# STM32MP21_CA35 register map
File version: 0.4
CPU: CM33 r0p1, little endian, MPU, FPU, vendor SysTick, 8 interrupt priority bits
Registers are 32-bit, read-write, reset 0x0 unless marked. A register's access mark holds for its fields unless they carry their own. Offsets are from the block's base; [hi:lo] are bit positions; {n}, {i} and the like mark numbered series; 'fields as' and 'values as' point back to an identical list.

## FDCAN1 (part 1 of 2) — FDCAN address block description
Base 0x402D0000
Same registers: FDCAN2 0x402E0000, FDCAN1_S 0x502D0000, FDCAN2_S 0x502E0000
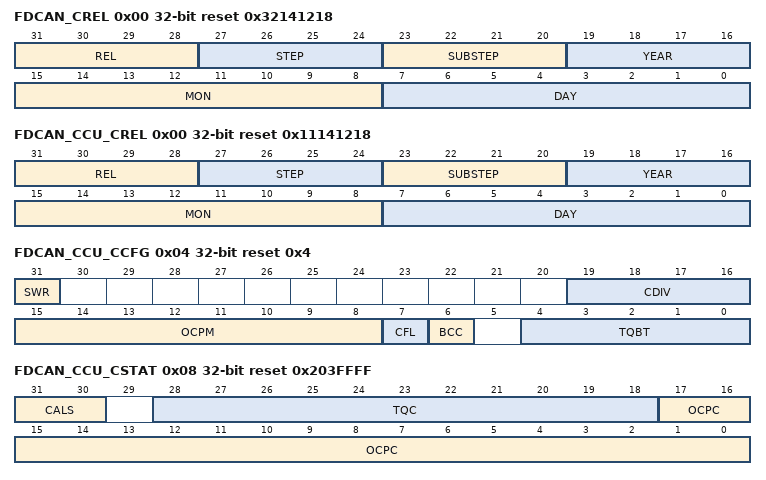
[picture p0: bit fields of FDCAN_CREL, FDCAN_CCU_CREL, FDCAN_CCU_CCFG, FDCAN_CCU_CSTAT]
0x00 FDCAN_CREL ro reset 0x32141218 — FDCAN core release register
  [31:28] REL — Core release = 3
  [27:24] STEP — Step of core release = 2
  [23:20] SUBSTEP — Sub-step of core release = 1
  [19:16] YEAR — Timestamp year = 4
  [15:8] MON — Timestamp month = 12
  [7:0] DAY — Timestamp day =18
0x00 FDCAN_CCU_CREL ro reset 0x11141218 (alternate view of FDCAN_CREL) — Clock calibration unit core release register
  [31:28] REL — Core release = 1
  [27:24] STEP — Step of core release = 1
  [23:20] SUBSTEP — Sub-step of core release = 1
  [19:16] YEAR — Timestamp year =
  [15:8] MON — Timestamp month = 12
  [7:0] DAY — Timestamp day = 18
0x04 FDCAN_ENDN ro reset 0x87654321 — FDCAN Endian register
  [31:0] ETV — Endianness test value The endianness test value is 0x8765 4321.
0x04 FDCAN_CCU_CCFG reset 0x4 (alternate view of FDCAN_ENDN) — Calibration configuration register
  [31] SWR — Software reset Writing a 1 to this bit resets the calibration FSM to state Not_Calibrated (FDCAN_CCU_CSTAT.CALS = 00). The calibration watchdog value CWD.WDV is also reset. Registers FDCAN_CCFG, FDCAN_CCU_CSTAT and the calibration watchdog configuration CWD.WDC are unchanged. The bit remains set until reset is completed. Write access by the user to registers/bits marked with P = Protected Write is possible only when FDCAN control bits FDCAN_CCCR.CCE = 1 AND FDCAN_CCCR.INIT = 1.
  [19:16] CDIV — Clock divider The clock divider must be configured when the clock calibration is bypassed (BCC = 1) to ensure that the FDCAN requirement is fulfilled. Write access by the user to registers/bits marked with P = Protected Write is possible only when FDCAN control bits FDCAN_CCCR.CCE = 1 AND FDCAN_CCCR.INIT = 1.
    0=Divide by 1; 1=Divide by 2; 2=Divide by 4; 3=Divide by 6; 4=Divide by 8; 5=Divide by 10; 6=Divide by 12; 7=Divide by 14; 8=Divide by 16; 9=Divide by 18; 10=Divide by 20; 11=Divide by 22; 12=Divide by 24; 13=Divide by 26; 14=Divide by 28; 15=Divide by 30
  [15:8] OCPM — Oscillator clock periods minimum Configures the minimum number of periods in two CAN bit times. OCPM is used in basic calibration to avoid false measurements in case of glitches on the bus line. The configured number of periods is OCPM 32. The configuration depends on the frequency and the bitrate configured in FDCAN modules (from 125 kbit/s up to 1 Mbit/s). It is recommended to configure a value slightly below two CAN bit times. The reset value is 1.6 bit times at 80 MHz fdcan_ker_ck and 1 Mbit/s CAN bitrate. Write access by the user to registers/bits marked with P = Protected Write is possible only when FDCAN control bits FDCAN_CCCR.CCE = 1 AND FDCAN_CCCR.INIT = 1.
  [7] CFL — Calibration field length Write access by the user to registers/bits marked with P = Protected Write is possible only when FDCAN control bits FDCAN_CCCR.CCE = 1 AND FDCAN_CCCR.INIT = 1.
    0=Calibration field length is 32 bits; 1=Calibration field length is 64 bits
  [6] BCC — Bypass clock calibration If this bit is set, the clock input fdcan_ker_ck is routed to the time quanta clock through a clock divider configurable via CDIV. In this case the baudrate prescaler of the connected FDCANs must be configured to generate the FDCAN internal time quanta clock.
    0=Clock calibration unit generates time quanta clock; 1=Clock calibration unit bypassed (default configuration)
  [4:0] TQBT — Time quanta per bit time Configures the number of time quanta per bit time. Same value as configured in FDCAN modules. The range of the resulting time quanta clock fdcan_tq_ck is from 0.5 MHz (bitrate of 125 kbit/s with 4 tq per bit time) to 25 MHz (bitrate of 1 Mbit/s with 25 tq per bit time). Valid values are 4 to 25. Configured values below 4 are interpreted as 4, values above 25 are interpreted as 25. Write access by the user to registers/bits marked with P = Protected Write is possible only when FDCAN control bits FDCAN_CCCR.CCE = 1 AND FDCAN_CCCR.INIT = 1.
0x08 FDCAN_CCU_CSTAT ro reset 0x203FFFF — Calibration status register
  [31:30] CALS — Calibration state
    0=Not_Calibrated; 1=Basic_Calibrated; 2=Precision_Calibrated
  [28:18] TQC — Time quanta counter Captured number of time quanta in calibration field (32 or 64 bits). Only valid when the clock calibration unit is in state Precision_Calibrated.
  [17:0] OCPC — Oscillator clock period counter Captured number of oscillator clock periods in calibration field (32 or 64 bits). Only valid when the clock calibration unit is in state Precision_Calibrated.
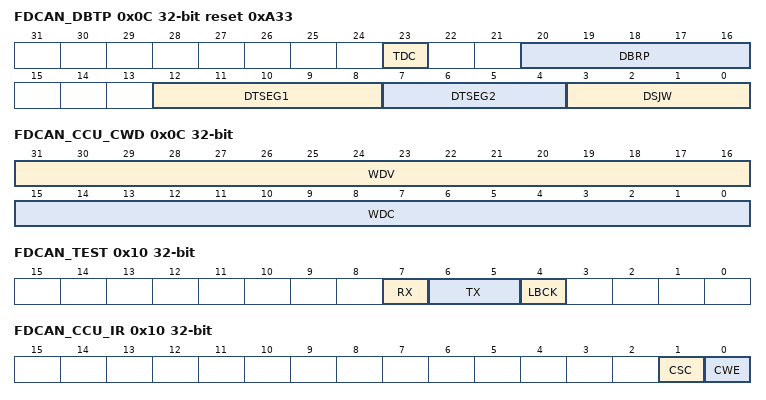
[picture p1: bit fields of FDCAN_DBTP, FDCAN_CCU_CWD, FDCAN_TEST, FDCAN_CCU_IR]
0x0C FDCAN_DBTP reset 0xA33 — FDCAN data bit timing and prescaler register
  [23] TDC — Transceiver delay compensation
    0=Transceiver delay compensation disabled; 1=Transceiver delay compensation enabled
  [20:16] DBRP — Data bitrate prescaler The value by which the oscillator frequency is divided to generate the bit time quanta. The bit time is built up from a multiple of these quanta. Valid values for the baudrate prescaler are 0 to 31. The hardware interpreters this value as the programmed value plus 1.
  [12:8] DTSEG1 — Data time segment before sample point Valid values are 0 to 31. The value used by the hardware is the one programmed, incremented by 1, i.e. tsubsuperiorBS1/subsuperior = (DTSEG1 + 1) x tq.
  [7:4] DTSEG2 — Data time segment after sample point Valid values are 0 to 15. The value used by the hardware is the one programmed, incremented by 1, i.e. tsubsuperiorBS2/subsuperior = (DTSEG2 + 1) x tq.
  [3:0] DSJW — Synchronization jump width Valid values are 0 to 15. The value used by the hardware is the one programmed, incremented by 1, i.e. tsubsuperiorSJW/subsuperior = (DSJW + 1) x tq.
0x0C FDCAN_CCU_CWD (alternate view of FDCAN_DBTP) — Calibration watchdog register
  [31:16] WDV ro — Watchdog value Actual calibration watchdog counter value.
  [15:0] WDC — WDC Watchdog configuration Start value of the calibration watchdog counter. With the reset value of 00 the counter is disabled. Write access by the user to registers/bits marked with P = Protected Write is possible only when FDCAN control bits FDCAN_CCCR.CCE = 1 AND FDCAN_CCCR.INIT = 1.
0x10 FDCAN_TEST
  [7] RX ro — Receive pin Monitors the actual value of transmit pin FDCANx_RX
    0=The CAN bus is dominant (FDCANx_RX = 0); 1=The CAN bus is recessive (FDCANx_RX = 1)
  [6:5] TX — Control of transmit pin
    0=Reset value , FDCANx_TX TX is controlled by the CAN core, updated at the end of the CAN bit time; 1=Sample point can be monitored at pin FDCANx_TX; 2=Dominant (0) level at pin FDCANx_TX; 3=Recessive (1) at pin FDCANx_TX
  [4] LBCK — Loop back mode
    0=Reset value, loop back mode is disabled; 1=Loop back mode is enabled (see Test modes)
0x10 FDCAN_CCU_IR (alternate view of FDCAN_TEST) — Clock calibration unit interrupt register
  [1] CSC — Calibration state changed
    0=Calibration state unchanged; 1=Calibration state has changed
  [0] CWE — Calibration watchdog event
    0=No calibration watchdog event; 1=Calibration watchdog event occurred
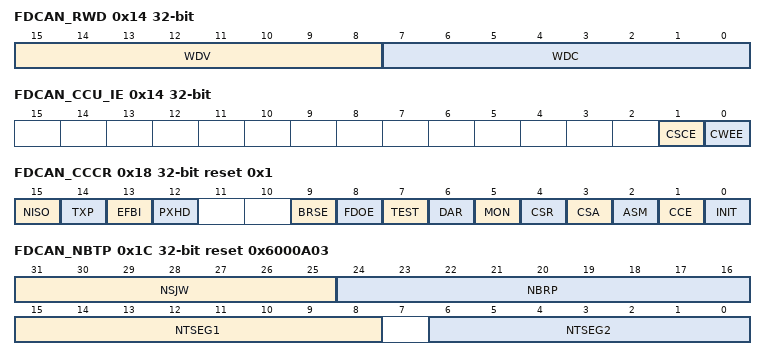
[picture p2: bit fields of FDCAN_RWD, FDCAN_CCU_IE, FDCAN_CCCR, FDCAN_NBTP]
0x14 FDCAN_RWD — FDCAN RAM watchdog register
  [15:8] WDV ro — Watchdog value Actual message RAM watchdog counter value.
  [7:0] WDC — Watchdog configuration Start value of the message RAM watchdog counter. With the reset value of 00 the counter is disabled. These are write-protected bits, write access is possible only when bit CCE and bit INIT of FDCAN_CCCR register are set to 1.
0x14 FDCAN_CCU_IE (alternate view of FDCAN_RWD) — Clock calibration unit interrupt enable register
  [1] CSCE — Calibration state changed enable
    0=Interrupt disabled; 1=Interrupt enabled
  [0] CWEE — Calibration watchdog event enable
    0=Interrupt disabled; 1=Interrupt enabled
0x18 FDCAN_CCCR reset 0x1 — FDCAN CC control register
  [15] NISO — Non ISO operation If this bit is set, the FDCAN uses the CAN FD frame format as specified by the Bosch CAN FD Specification V1.0.
    0=CAN FD frame format according to ISO11898-1; 1=CAN FD frame format according to Bosch CAN FD Specification V1.0
  [14] TXP — If this bit is set, the FDCAN pauses for two CAN bit times before starting the next transmission after successfully transmitting a frame.
    0=Disabled; 1=Enabled
  [13] EFBI — Edge filtering during bus integration
    0=Edge filtering disabled; 1=Two consecutive dominant tq required to detect an edge for hard synchronization
  [12] PXHD — Protocol exception handling disable
    0=Protocol exception handling enabled; 1=Protocol exception handling disabled
  [9] BRSE — FDCAN bitrate switching
    0=Bitrate switching for transmissions disabled; 1=Bitrate switching for transmissions enabled
  [8] FDOE — FD operation enable
    0=FD operation disabled; 1=FD operation enabled
  [7] TEST — Test mode enable
    0=Normal operation, register TEST holds reset values; 1=Test mode, write access to register TEST enabled
  [6] DAR — Disable automatic retransmission
    0=Automatic retransmission of messages not transmitted successfully enabled; 1=Automatic retransmission disabled
  [5] MON — Bus monitoring mode Bit MON can be set only by software when both CCE and INIT are set to 1. The bit can be reset by the user at any time.
    0=Bus monitoring mode is disabled; 1=Bus monitoring mode is enabled
  [4] CSR — Clock stop request after all pending transfer requests have been completed and the CAN bus reached idle.
    0=No clock stop is requested; 1=Clock stop requested. When clock stop is requested, first INIT and then CSA is set
  [3] CSA ro — Clock stop acknowledge
    0=No clock stop acknowledged; 1=FDCAN may be set in power down by stopping APB clock and kernel clock
  [2] ASM — ASM restricted operation mode The restricted operation mode is intended for applications that adapt themselves to different CAN bitrates. The application tests different bitrates and leaves the restricted operation mode after it has received a valid frame. In the optional restricted operation mode the node is able to transmit and receive data and remote frames and it gives acknowledge to valid frames, but it does not send active error frames or overload frames. In case of an error condition or overload condition, it does not send dominant bits, instead it waits for the occurrence of bus idle condition to resynchronize itself to the CAN communication. The error counters are not incremented. Bit ASM can be set only by software when both CCE and INIT are set to 1. The bit can be reset by the software at any time. This bit is set automatically set to 1 when the Tx handler was not able to read data from the message RAM in time. If the FDCAN is connected to a clock calibration on CAN unit, ASM bit is set by hardware as long as the calibration is not completed.
    0=Normal CAN operation; 1=Restricted operation mode active
  [1] CCE — Configuration change enable
    0=The CPU has no write access to the protected configuration registers; 1=The CPU has write access to the protected configuration registers (while FDCAN_CCCR.INIT = 1 CCE bit is automatically cleared when INIT bit is cleared)
  [0] INIT — Initialization
    0=Normal operation; 1=Initialization is started (while FDCAN_CCCR.INIT = 1 CCE bit is automatically cleared when INIT bit is cleared)
0x1C FDCAN_NBTP reset 0x6000A03 — FDCAN nominal bit timing and prescaler register
  [31:25] NSJW — Nominal (re)synchronization jump width Should be smaller than NTSEG2, valid values are 0 to 127. The value used by the hardware is the one programmed, incremented by 1, i.e. tsubsuperiorSJW/subsuperior = (NSJW + 1) x tq. These are write-protected bits, write access is possible only when bit CCE and bit INIT of FDCAN_CCCR register are set to 1.
  [24:16] NBRP — Bitrate prescaler Value by which the oscillator frequency is divided for generating the bit time quanta. The bit time is built up from a multiple of this quanta. Valid values are 0 to 511. The value used by the hardware is the one programmed, incremented by 1. These are write-protected bits, write access is possible only when bit CCE and bit INIT of FDCAN_CCCR register are set to 1.
  [15:8] NTSEG1 — Nominal time segment before sample point Valid values are 0 to 255. The value used by the hardware is the one programmed, incremented by 1 (tsubsuperiorBS1/subsuperior = (NTSEG1 + 1) x tq). These are write-protected bits, write access is possible only when bit CCE and bit INIT of FDCAN_CCCR register are set to 1.
  [6:0] NTSEG2 — Nominal time segment after sample point Valid values are 0 to 127. The value used by the hardware is the one programmed, incremented by 1 (tsubsuperiorBS2/subsuperior = (NTSEG2 + 1) x tq).
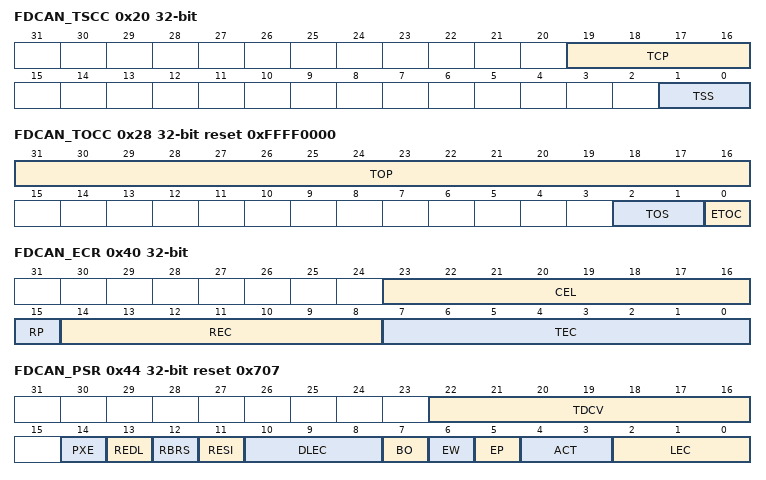
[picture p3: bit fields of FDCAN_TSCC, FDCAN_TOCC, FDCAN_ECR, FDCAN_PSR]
0x20 FDCAN_TSCC — FDCAN timestamp counter configuration register
  [19:16] TCP — Timestamp counter prescaler Configures the timestamp and timeout counters time unit in multiples of CAN bit times [1 .. 16]. The actual interpretation by the hardware of this value is such that one more than the value programmed here is used. In CAN FD mode the internal timestamp counter TCP does not provide a constant time base due to the different CAN bit times between arbitration phase and data phase. Thus CAN FD requires an external counter for timestamp generation (TSS = 10). These are write-protected bits, write access is possible only when bit CCE and bit INIT of FDCAN_CCCR register are set to 1.
  [1:0] TSS — Timestamp select These are write-protected bits, write access is possible only when bit CCE and bit INIT of FDCAN_CCCR register are set to 1.
    0=Timestamp counter value always 0x0000; 1=Timestamp counter value incremented according to TCP; 2=External timestamp counter from TIM3 value used (tim3_cnt[0:15]); 3=Same as 00
0x24 FDCAN_TSCV — FDCAN timestamp counter value register
  [15:0] TSC — Timestamp counter The internal/external timestamp counter value is captured on start of frame (both Rx and Tx). When FDCAN_TSCC.TSS = 01, the timestamp counter is incremented in multiples of CAN bit times [1 .. 16] depending on the configuration of FDCAN_TSCC.TCP. A wrap around sets interrupt flag FDCAN_IR.TSW. Write access resets the counter to 0. When FDCAN_TSCC.TSS = 10, TSC reflects the external timestamp counter value. A write access has no impact.
0x28 FDCAN_TOCC reset 0xFFFF0000 — FDCAN timeout counter configuration register
  [31:16] TOP — Timeout period Start value of the timeout counter (down-counter). Configures the timeout period. These are write-protected bits, write access is possible only when bit CCE and bit INIT of FDCAN_CCCR register are set to 1.
  [2:1] TOS — Timeout select When operating in Continuous mode, a write to FDCAN_TOCV presets the counter to the value configured by FDCAN_TOCC.TOP and continues down-counting. When the timeout counter is controlled by one of the FIFOs, an empty FIFO presets the counter to the value configured by FDCAN_TOCC.TOP. Down-counting is started when the first FIFO element is stored. These are write-protected bits, write access is possible only when bit CCE and bit INIT of FDCAN_CCCR register are set to 1.
    0=Continuous operation; 1=Timeout controlled by Tx event FIFO; 2=Timeout controlled by Rx FIFO 0; 3=Timeout controlled by Rx FIFO 1
  [0] ETOC — Enable timeout counter This is a write-protected bit, write access is possible only when the bit 1 (CCE) and bit 0 (INIT) of FDCAN_CCCR register are set to 1.
    0=Timeout counter disabled; 1=Timeout counter enabled
0x2C FDCAN_TOCV reset 0xFFFF — FDCAN timeout counter value register
  [15:0] TOC — Timeout counter The timeout counter is decremented in multiples of CAN bit times [1 .. 16] depending on the configuration of FDCAN_TSCC.TCP. When decremented to 0, interrupt flag FDCAN_IR.TOO is set and the timeout counter is stopped. Start and reset/restart conditions are configured via FDCAN_TOCC.TOS.
0x40 FDCAN_ECR — FDCAN error counter register
  [23:16] CEL — CAN error logging The counter is incremented each time when a CAN protocol error causes the transmit error counter or the receive error counter to be incremented. It is reset by read access to CEL. The counter stops at 0xFF; the next increment of TEC or REC sets interrupt flag FDCAN_IR.ELO.
  [15] RP ro — Receive error passive
    0=The receive error counter is below the error passive level of 128; 1=The receive error counter has reached the error passive level of 128
  [14:8] REC ro — Receive error counter Actual state of the receive error counter, values between 0 and 127.
  [7:0] TEC ro — Transmit error counter Actual state of the transmit error counter, values between 0 and 255. When FDCAN_CCCR.ASM is set, the CAN protocol controller does not increment TEC and REC when a CAN protocol error is detected, but CEL is still incremented.
0x44 FDCAN_PSR reset 0x707 — FDCAN protocol status register
  [22:16] TDCV ro — Transmitter delay compensation value Position of the secondary sample point, defined by the sum of the measured delay from FDCAN_TX to FDCAN_RX and FDCAN_TDCR.TDCO. The SSP position is, in the data phase, the number of minimum time quanta (mtq) between the start of the transmitted bit and the secondary sample point. Valid values are 0 to 127 mtq.
  [14] PXE — Protocol exception event
    0=No protocol exception event occurred since last read access; 1=Protocol exception event occurred
  [13] REDL — Received FDCAN message This bit is set independent of acceptance filtering. Access type is RX: reset on read.
    0=Since this bit was reset by the CPU, no FDCAN message has been received; 1=Message in FDCAN format with EDL flag set has been received
  [12] RBRS — BRS flag of last received FDCAN message This bit is set together with REDL, independent of acceptance filtering. Access type is RX: reset on read.
    0=Last received FDCAN message did not have its BRS flag set; 1=Last received FDCAN message had its BRS flag set
  [11] RESI — ESI flag of last received FDCAN message This bit is set together with REDL, independent of acceptance filtering. Access type is RX: reset on read.
    0=Last received FDCAN message did not ha ve its ESI flag set; 1=Last received FDCAN message had its ESI flag set
  [10:8] DLEC ro — Data last error code Type of last error that occurred in the data phase of an FDCAN format frame with its BRS flag set. Coding is the same as for LEC. This field is cleared to 0 when an FDCAN format frame with its BRS flag set has been transferred (reception or transmission) without error. Access type is RS: set on read.
  [7] BO ro — Bus_Off status
    0=The FDCAN is not Bus_Off; 1=The FDCAN is in Bus_Off state
  [6] EW ro — Warning status
    0=Both error counters are below the Error_Warning limit of 96; 1=At least one of error counter has reached the Error_Warning limit of 96
  [5] EP ro — Error passive
    0=The FDCAN is in the Error_Active state. It normally takes part in bus communication and sends an active error flag when an error has been detected; 1=The FDCAN is in the Error_Passive state
  [4:3] ACT ro — Activity Monitors the module CAN communication state.
    0=Synchronizing: node is synchronizing on CAN communication; 1=Idle: node is neither receiver nor transmitter; 2=Receiver: node is operating as receiver; 3=Transmitter: node is operating as transmitter
  [2:0] LEC ro — Last error code The LEC indicates the type of the last error to occur on the CAN bus. This field is cleared to 0 when a message has been transferred (reception or transmission) without error. Access type is RS: set on read.
    0=No error: No error occurred since LEC has been reset by successful reception or transmission; 1=Stuff error: More than 5 equal bits in a sequence have occurred in a part of a received message where this is not allowed; 2=Form error: A fixed format part of a received frame has the wrong format; 3=AckError: The message transmitted by the FDCAN was not acknowledged by another node; 4=Bit1Error: During the transmission of a message (with the exception of the arbitration field), the device wanted to send a recessive level (bit of logical value 1), but the monitored bus value was dominant; 5=Bit0Error: During the transmission of a message (or acknowledge bit, or active error flag, or overload flag), the device wanted to send a dominant level (data or identifier bit logical value 0), but the monitored bus value was recessive. During Bus_Off recovery this status is set each time a sequence of 11 recessive bits has been monitored. This enables the CPU to monitor the proceeding of the Bus_Off recovery sequence (indicating the bus is not stuck at dominant or continuously disturbed).; 6=CRCError: The CRC check sum of a received message was incorrect. The CRC of an incoming message does not match with the CRC calculated from the received data.; 7=NoChange: Any read access to the protocol status register re-initializes the LEC to '7. When the LEC shows the value 7, no CAN bus event was detected since the last CPU read access to the protocol status register.
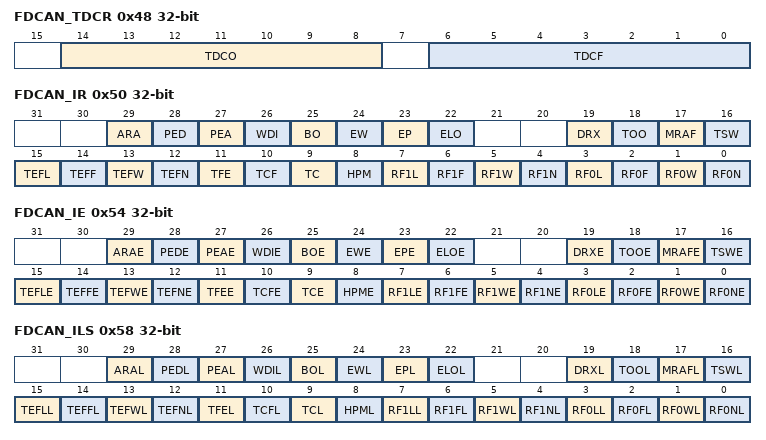
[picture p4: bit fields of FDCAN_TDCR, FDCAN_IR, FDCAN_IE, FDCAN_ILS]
0x48 FDCAN_TDCR — FDCAN transmitter delay compensation register
  [14:8] TDCO — Transmitter delay compensation offset Offset value defining the distance between the measured delay from FDCAN_TX to FDCAN_RX and the secondary sample point. Valid values are 0 to 127 mtq. These are write-protected bits, which means that write access by the bits is possible only when the bit CCE and bit INIT of FDCAN_CCCR register are set to 1.
  [6:0] TDCF — Transmitter delay compensation filter window length Defines the minimum value for the SSP position, dominant edges on FDCAN_RX that would result in an earlier SSP position are ignored for transmitter delay measurements. These are write-protected bits, which means that write access by the bits is possible only when the bit CCE and bit INIT of FDCAN_CCCR register are set to 1.
0x50 FDCAN_IR — FDCAN interrupt register
  [29] ARA — Access to reserved address
    0=No access to reserved address occurred; 1=Access to reserved address occurred
  [28] PED — Protocol error in data phase (data bit time is used)
    0=No protocol error in data phase; 1=Protocol error in data phase detected (PSR.DLEC different from 0,7)
  [27] PEA — Protocol error in arbitration phase (nominal bit time is used)
    0=No protocol error in arbitration phase; 1=Protocol error in arbitration phase detected (PSR.LEC different from 0,7)
  [26] WDI — Watchdog interrupt
    0=No message RAM watchdog event occurred; 1=Message RAM watchdog event due to missing READY
  [25] BO — Bus_Off status
    0=Bus_Off status unchanged; 1=Bus_Off status changed
  [24] EW — Warning status
    0=Error_Warning status unchanged; 1=Error_Warning status changed
  [23] EP — Error passive
    0=Error_Passive status unchanged; 1=Error_Passive status changed
  [22] ELO — Error logging overflow
    0=CAN error logging counter did not overflow; 1=Overflow of CAN error logging counter occurred
  [19] DRX — Message stored to dedicated Rx buffer The flag is set whenever a received message has been stored into a dedicated Rx buffer.
    0=No Rx buffer updated; 1=At least one received message stored into a Rx buffer
  [18] TOO — Timeout occurred
    0=No timeout; 1=Timeout reached
  [17] MRAF — Message RAM access failure The flag is set when the Rx handler Has not completed acceptance filtering or storage of an accepted message until the arbitration field of the following message has been received. In this case acceptance filtering or message storage is aborted and the Rx handler starts processing of the following message. Was unable to write a message to the message RAM. In this case message storage is aborted. In both cases the FIFO put index is not updated or the New data flag for a dedicated Rx buffer is not set. The partly stored message is overwritten when the next message is stored to this location. The flag is also set when the Tx handler was not able to read a message from the message RAM in time. In this case message transmission is aborted. In case of a Tx handler access failure the FDCAN is switched into restricted operation mode (see Restricted operation mode). To leave restricted operation mode, the user has to reset FDCAN_CCCR.ASM.
    0=No message RAM access failure occurred; 1=Message RAM access failure occurred
  [16] TSW — Timestamp wraparound
    0=No timestamp counter wraparound; 1=Timestamp counter wraparound
  [15] TEFL — Tx event FIFO element lost
    0=No Tx event FIFO element lost; 1=Tx event FIFO element lost, also set after write attempt to Tx event FIFO of size 0
  [14] TEFF — Tx event FIFO full
    0=Tx event FIFO not full; 1=Tx event FIFO full
  [13] TEFW — Tx event FIFO watermark reached
    0=Tx event FIFO fill level below watermark; 1=Tx event FIFO fill level reached watermark
  [12] TEFN — Tx event FIFO new entry
    0=Tx event FIFO unchanged; 1=Tx handler wrote Tx event FIFO element
  [11] TFE — Tx FIFO empty
    0=Tx FIFO non-empty; 1=Tx FIFO empty
  [10] TCF — Transmission cancellation finished
    0=No transmission cancellation finished; 1=Transmission cancellation finished
  [9] TC — Transmission completed
    0=No transmission completed; 1=Transmission completed
  [8] HPM — High priority message
    0=No high priority message received; 1=High priority message received
  [7] RF1L — Rx FIFO 1 message lost
    0=No Rx FIFO 1 message lost; 1=Rx FIFO 1 message lost, also set after write attempt to Rx FIFO 1 of size 0
  [6] RF1F — Rx FIFO 1 full
    0=Rx FIFO 1 not full; 1=Rx FIFO 1 full
  [5] RF1W — Rx FIFO 1 watermark reached
    0=Rx FIFO 1 fill level below watermark; 1=Rx FIFO 1 fill level reached watermark
  [4] RF1N — Rx FIFO 1 new message
    0=No new message written to Rx FIFO 1; 1=New message written to Rx FIFO 1
  [3] RF0L — Rx FIFO 0 message lost
    0=No Rx FIFO 0 message lost; 1=Rx FIFO 0 message lost, also set after write attempt to Rx FIFO 0 of size 0
  [2] RF0F — Rx FIFO 0 full
    0=Rx FIFO 0 not full; 1=Rx FIFO 0 full
  [1] RF0W — Rx FIFO 0 watermark reached
    0=Rx FIFO 0 fill level below watermark; 1=Rx FIFO 0 fill level reached watermark
  [0] RF0N — Rx FIFO 0 New message
    0=No new message written to Rx FIFO 0; 1=New message written to Rx FIFO 0
0x54 FDCAN_IE — FDCAN interrupt enable register
  [29] ARAE — Access to Reserved address enable
  [28] PEDE — Protocol error in data phase enable
  [27] PEAE — Protocol error in Arbitration phase enable
  [26] WDIE — Watchdog interrupt enable
    0=Interrupt disabled; 1=Interrupt enabled
  [25] BOE — Bus_Off status
    0=Interrupt disabled; 1=Interrupt enabled
  [24] EWE — Warning status interrupt enable
    0=Interrupt disabled; 1=Interrupt enabled
  [23] EPE — Error passive interrupt enable
    0=Interrupt disabled; 1=Interrupt enabled
  [22] ELOE — Error logging overflow interrupt enable
    0=Interrupt disabled; 1=Interrupt enabled
  [19] DRXE — Message stored to dedicated Rx buffer interrupt enable
    0=Interrupt disabled; 1=Interrupt enabled
  [18] TOOE — Timeout occurred interrupt enable
    0=Interrupt disabled; 1=Interrupt enabled
  [17] MRAFE — Message RAM access failure interrupt enable
    0=Interrupt disabled; 1=Interrupt enabled
  [16] TSWE — Timestamp wraparound interrupt enable
    0=Interrupt disabled; 1=Interrupt enabled
  [15] TEFLE — Tx event FIFO element lost interrupt enable
    0=Interrupt disabled; 1=Interrupt enabled
  [14] TEFFE — Tx event FIFO full interrupt enable
    0=Interrupt disabled; 1=Interrupt enabled
  [13] TEFWE — Tx event FIFO watermark reached interrupt enable
    0=Interrupt disabled; 1=Interrupt enabled
  [12] TEFNE — Tx event FIFO new entry interrupt enable
    0=Interrupt disabled; 1=Interrupt enabled
  [11] TFEE — Tx FIFO empty interrupt enable
    0=Interrupt disabled; 1=Interrupt enabled
  [10] TCFE — Transmission cancellation finished interrupt enable
    0=Interrupt disabled; 1=Interrupt enabled
  [9] TCE — Transmission completed interrupt enable
    0=Interrupt disabled; 1=Interrupt enabled
  [8] HPME — High priority message interrupt enable
    0=Interrupt disabled; 1=Interrupt enabled
  [7] RF1LE — Rx FIFO 1 message lost interrupt enable
    0=Interrupt disabled; 1=Interrupt enabled
  [6] RF1FE — Rx FIFO 1 full interrupt enable
    0=Interrupt disabled; 1=Interrupt enabled
  [5] RF1WE — Rx FIFO 1 watermark reached interrupt enable
    0=Interrupt disabled; 1=Interrupt enabled
  [4] RF1NE — Rx FIFO 1 new message interrupt enable
    0=Interrupt disabled; 1=Interrupt enabled
  [3] RF0LE — Rx FIFO 0 message lost interrupt enable
    0=Interrupt disabled; 1=Interrupt enabled
  [2] RF0FE — Rx FIFO 0 full interrupt enable
    0=Interrupt disabled; 1=Interrupt enabled
  [1] RF0WE — Rx FIFO 0 watermark reached interrupt enable
    0=Interrupt disabled; 1=Interrupt enabled
  [0] RF0NE — Rx FIFO 0 new message interrupt enable
    0=Interrupt disabled; 1=Interrupt enabled
0x58 FDCAN_ILS — FDCAN interrupt line select register
  [29] ARAL — Access to reserved address line
  [28] PEDL — Protocol error in data phase line
  [27] PEAL — Protocol error in arbitration phase line
  [26] WDIL — Watchdog interrupt line
  [25] BOL — Bus_Off status
  [24] EWL — Warning status interrupt line
  [23] EPL — Error passive interrupt line
  [22] ELOL — Error logging overflow interrupt line
  [19] DRXL — Message stored to dedicated Rx buffer interrupt line
  [18] TOOL — Timeout occurred interrupt line
  [17] MRAFL — Message RAM access failure interrupt line
  [16] TSWL — Timestamp wraparound interrupt line
  [15] TEFLL — Tx event FIFO element Lost interrupt line
  [14] TEFFL — Tx event FIFO full interrupt line
  [13] TEFWL — Tx event FIFO watermark reached interrupt line
  [12] TEFNL — Tx event FIFO new entry interrupt line
  [11] TFEL — Tx FIFO empty interrupt line
  [10] TCFL — Transmission cancellation finished interrupt line
  [9] TCL — Transmission completed interrupt line
  [8] HPML — High priority message interrupt line
  [7] RF1LL — Rx FIFO 1 message lost interrupt line
  [6] RF1FL — Rx FIFO 1 full interrupt line
  [5] RF1WL — Rx FIFO 1 watermark reached interrupt line
  [4] RF1NL — Rx FIFO 1 new message interrupt line
  [3] RF0LL — Rx FIFO 0 message lost interrupt line
  [2] RF0FL — Rx FIFO 0 full interrupt line
  [1] RF0WL — Rx FIFO 0 watermark reached interrupt line
  [0] RF0NL — Rx FIFO 0 new message interrupt line
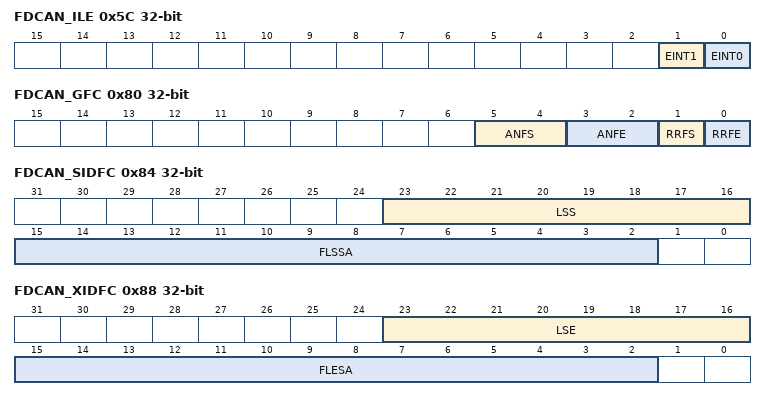
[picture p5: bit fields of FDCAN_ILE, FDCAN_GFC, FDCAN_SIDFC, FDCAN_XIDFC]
0x5C FDCAN_ILE — FDCAN interrupt line enable register
  [1] EINT1 — Enable interrupt line 1
    0=Interrupt line fdcan_intr1_it disabled; 1=Interrupt line fdcan_intr1_it enabled
  [0] EINT0 — Enable interrupt line 0
    0=Interrupt line fdcan_intr0_it disabled; 1=Interrupt line fdcan_intr0_it enabled
0x80 FDCAN_GFC — FDCAN global filter configuration register
  [5:4] ANFS — Accept non-matching frames standard Defines how received messages with 11-bit ID that do not match any element of the filter list are treated. These are write-protected bits, write access is possible only when bit CCE and bit INIT of FDCAN_CCCR register are set to 1.
    0=Accept in Rx FIFO 0; 1=Accept in Rx FIFO 1; 2=Reject; 3=Reject
  [3:2] ANFE — Accept non-matching frames extended Defines how received messages with 29-bit ID that do not match any element of the filter list are treated. These are write-protected bits, write access is possible only when bit CCE and bit INIT of FDCAN_CCCR register are set to 1.
    values as ANFS
  [1] RRFS — Reject remote frames standard These are write-protected bits, write access is possible only when bit CCE and bit INIT of FDCAN_CCCR register are set to 1.
    0=Filter remote frames with 11-bit standard ID; 1=Reject all remote frames with 11-bit standard ID
  [0] RRFE — Reject remote frames extended These are write-protected bits, write access is possible only when bit CCE and bit INIT of FDCAN_CCCR register are set to 1.
    0=Filter remote frames with 29-bit standard ID; 1=Reject all remote frames with 29-bit standard ID
0x84 FDCAN_SIDFC — FDCAN standard ID filter configuration register
  [23:16] LSS — List size standard 1-128: Number of standard message ID filter elements superior128: Values greater than 128 are interpreted as 128. These are write-protected bits, write access is possible only when bit CCE and bit INIT of FDCAN_CCCR register are set to 1.
    0=No standard message ID filter
  [15:2] FLSSA — Filter list standard start address Start address of standard message ID filter list (32-bit word address, see Table 843).These are write-protected bits, write access is possible only when bit CCE and bit INIT of FDCAN_CCCR register are set to 1.
0x88 FDCAN_XIDFC — FDCAN extended ID filter configuration register
  [23:16] LSE — List size extended 1-128: Number of extended ID filter elements superior128: Values greater than 128 are interpreted as 128. These are write-protected bits, write access is possible only when bit CCE and bit INIT of FDCAN_CCCR register are set to 1.
    0=No extended message ID filter
  [15:2] FLESA — Filter list extended start address Start address of extended message ID filter list (32-bit word address, see Table 845: Extended message ID filter element). These are write-protected bits, write access is possible only when bit CCE and bit INIT of FDCAN_CCCR register are set to 1.
0x90 FDCAN_XIDAM reset 0x1FFFFFFF — FDCAN extended ID and mask register
  [28:0] EIDM — Extended ID Mask For acceptance filtering of extended frames the extended ID AND Mask is AND-ed with the message ID of a received frame. Intended for masking of 29-bit IDs in SAE J1939. With the reset value of all bits set to 1 the mask is not active. These are write-protected bits, write access is possible only when bit CCE and bit INIT of FDCAN_CCCR register are set to 1.
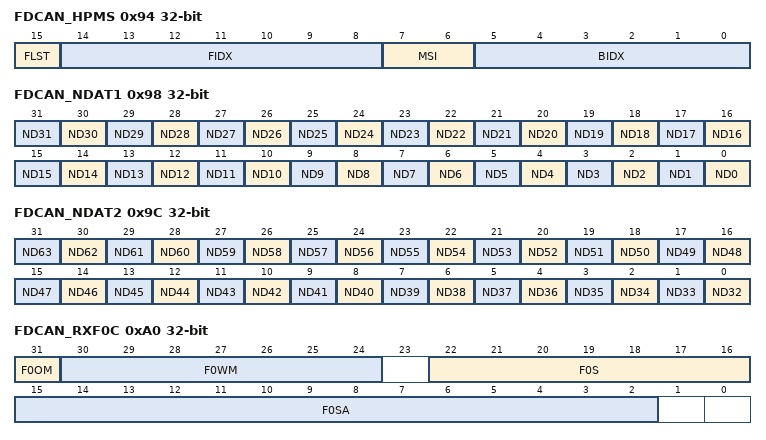
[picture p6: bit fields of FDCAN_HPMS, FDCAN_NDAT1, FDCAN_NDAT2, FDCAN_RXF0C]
0x94 FDCAN_HPMS ro — FDCAN high priority message status register
  [15] FLST — Filter list Indicates the filter list of the matching filter element.
    0=Standard filter list; 1=Extended filter list
  [14:8] FIDX — Filter index Index of matching filter element. Range is 0 to FDCAN_SIDFC[LSS] - 1 or FDCAN_XIDFC[LSE] - 1.
  [7:6] MSI — Message storage indicator
    0=No FIFO selected; 1=FIFO overrun; 2=Message stored in FIFO 0; 3=Message stored in FIFO 1
  [5:0] BIDX — Buffer index Index of Rx FIFO element to which the message was stored. Only valid when MSI[1] = 1.
0x98 FDCAN_NDAT1 — FDCAN new data 1 register
  [all] fields
    0=Rx buffer not updated; 1=Rx buffer updated from new message
  [n] ND{n} (n=0..31) — New data[31:0] The register holds the new data flags of Rx buffers 0 to 31. The flags are set when the respective Rx buffer has been updated from a received frame. The flags remain set until the user clears them. A flag is cleared by writing a 1 to the corresponding bit position. Writing a 0 has no effect. A hard reset clears the register.
0x9C FDCAN_NDAT2 — FDCAN new data 2 register
  [all] fields
    values as the fields of FDCAN_NDAT1
  [n-32] ND{n} (n=32..63) — New data[63:32] The register holds the new data flags of Rx buffers 32 to 63. The flags are set when the respective Rx buffer has been updated from a received frame. The flags remain set until the user clears them. A flag is cleared by writing a 1 to the corresponding bit position. Writing a 0 has no effect. A hard reset clears clear the register.
0xA0 FDCAN_RXF0C — FDCAN Rx FIFO 0 configuration register
  [31] F0OM — FIFO 0 operation mode FIFO 0 can be operated in blocking or in overwrite mode.
    0=FIFO 0 blocking mode; 1=FIFO 0 overwrite mode
  [30:24] F0WM — FIFO 0 watermark 1-64: Level for Rx FIFO 0 watermark interrupt (FDCAN_IR.RF0W) superior64: Watermark interrupt disabled These are write-protected bits, write access is possible only when bit CCE and bit INIT of FDCAN_CCCR register are set to 1.
    0=Watermark interrupt disabled
  [22:16] F0S — Rx FIFO 0 size 1-64: Number of Rx FIFO 0 elements superior64: Values greater than 64 are interpreted as 64 The Rx FIFO 0 elements are indexed from 0 to F0S-1.
    0=No Rx FIFO 0
  [15:2] F0SA — Rx FIFO 0 start address Start address of Rx FIFO 0 in message RAM (32-bit word address, see Figure 1033).
